# ATxmega128D4 device description
Architecture: AVR8_XMEGA; Family: AVR XMEGA
Registers are 8-bit, access not given, no defined reset value unless marked. A register's access mark holds for its fields unless they carry their own. Offsets are from the block's base; [hi:lo] are bit positions; lines under a group give offsets from that group; {n}, {i} and the like mark numbered series; 'fields as' and 'values as' point back to an identical list.

## RTC — Real-Time Counter
Instances: RTC 0x0400
0x00 CTRL — Control Register
  [2:0] PRESCALER — Prescaling Factor
    0=OFF (RTC Off); 1=DIV1 (RTC Clock); 2=DIV2 (RTC Clock / 2); 3=DIV8 (RTC Clock / 8); 4=DIV16 (RTC Clock / 16); 5=DIV64 (RTC Clock / 64); 6=DIV256 (RTC Clock / 256); 7=DIV1024 (RTC Clock / 1024)
0x01 STATUS
  [0] SYNCBUSY — Synchronization Busy Flag
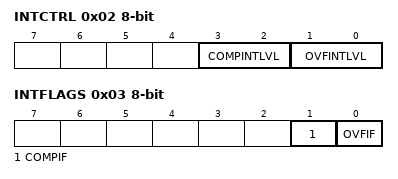
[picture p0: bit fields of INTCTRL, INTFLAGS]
0x02 INTCTRL — Interrupt Control Register
  [3:2] COMPINTLVL — Compare Match Interrupt Level
    0=OFF (Interrupt Disabled); 1=LO (Low Level); 2=MED (Medium Level); 3=HI (High Level)
  [1:0] OVFINTLVL — Overflow Interrupt Level
    values as COMPINTLVL
0x03 INTFLAGS — Interrupt Flags
  [1] COMPIF — Compare Match Interrupt Flag
  [0] OVFIF — Overflow Interrupt Flag
0x04 TEMP — Temporary register
0x08 CNT 16-bit — Count Register
0x0A PER 16-bit — Period Register
0x0C COMP 16-bit — Compare Register

## TWI — Two-Wire Interface
Instances: TWIC 0x480, TWIE 0x4A0
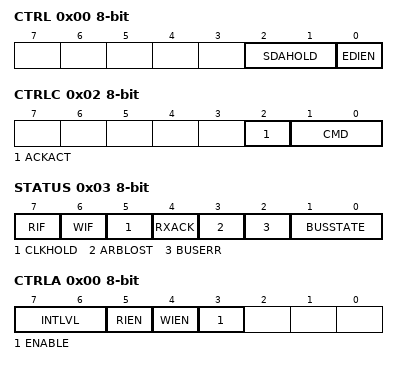
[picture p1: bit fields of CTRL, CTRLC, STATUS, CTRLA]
0x00 CTRL — TWI Common Control Register
  [2:1] SDAHOLD — SDA Hold Time Enable
    0=OFF (SDA Hold Time off); 1=50NS (SDA Hold Time 50 ns); 2=300NS (SDA Hold Time 300 ns); 3=400NS (SDA Hold Time 400 ns)
  [0] EDIEN — External Driver Interface Enable
0x01 MASTER group — TWI master module
  0x00 CTRLA — Control Register A
    [7:6] INTLVL — Interrupt Level
      0=OFF (Interrupt Disabled); 1=LO (Low Level); 2=MED (Medium Level); 3=HI (High Level)
    [5] RIEN — Read Interrupt Enable
    [4] WIEN — Write Interrupt Enable
    [3] ENABLE — Enable TWI Master
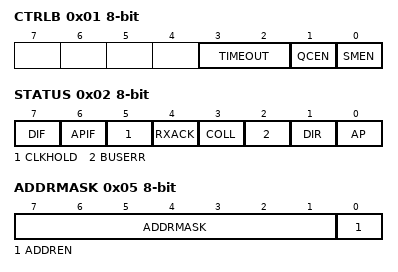
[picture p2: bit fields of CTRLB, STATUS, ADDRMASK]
  0x01 CTRLB — Control Register B
    [3:2] TIMEOUT — Inactive Bus Timeout
      0=DISABLED (Bus Timeout Disabled); 1=50US (50 Microseconds); 2=100US (100 Microseconds); 3=200US (200 Microseconds)
    [1] QCEN — Quick Command Enable
    [0] SMEN — Smart Mode Enable
  0x02 CTRLC — Control Register C
    [2] ACKACT — Acknowledge Action
    [1:0] CMD — Command
      0=NOACT (No Action); 1=REPSTART (Issue Repeated Start Condition); 2=RECVTRANS (Receive or Transmit Data); 3=STOP (Issue Stop Condition)
  0x03 STATUS
    [7] RIF — Read Interrupt Flag
    [6] WIF — Write Interrupt Flag
    [5] CLKHOLD — Clock Hold
    [4] RXACK — Received Acknowledge
    [3] ARBLOST — Arbitration Lost
    [2] BUSERR — Bus Error
    [1:0] BUSSTATE
      0=UNKNOWN (Unknown Bus State); 1=IDLE (Bus is Idle); 2=OWNER (This Module Controls The Bus); 3=BUSY (The Bus is Busy)
  0x04 BAUD — Baurd Rate Control Register
  0x05 ADDR — Address Register
  0x06 DATA
0x08 SLAVE group — TWI slave module
  0x00 CTRLA — Control Register A
    [7:6] INTLVL — Interrupt Level
      values as MASTER.CTRLA.INTLVL
    [5] DIEN — Data Interrupt Enable
    [4] APIEN — Address/Stop Interrupt Enable
    [3] ENABLE — Enable TWI Slave
    [2] PIEN — Stop Interrupt Enable
    [1] PMEN — Promiscuous Mode Enable
    [0] SMEN — Smart Mode Enable
  0x01 CTRLB — Control Register B
    [2] ACKACT — Acknowledge Action
    [1:0] CMD — Command
      0=NOACT (No Action); 2=COMPTRANS (Used To Complete a Transaction); 3=RESPONSE (Used in Response to Address/Data Interrupt)
  0x02 STATUS
    [7] DIF — Data Interrupt Flag
    [6] APIF — Address/Stop Interrupt Flag
    [5] CLKHOLD — Clock Hold
    [4] RXACK — Received Acknowledge
    [3] COLL — Collision
    [2] BUSERR — Bus Error
    [1] DIR — Read/Write Direction
    [0] AP — Slave Address or Stop
  0x03 ADDR — Address Register
  0x04 DATA
  0x05 ADDRMASK — Address Mask Register
    [7:1] ADDRMASK — Address Mask
    [0] ADDREN — Address Enable

## PORT — I/O Ports
Instances: PORTA 0x0600, PORTB 0x0620, PORTC 0x0640, PORTD 0x0660, PORTE 0x0680, PORTR 0x07E0
0x00 DIR — I/O Port Data Direction
0x01 DIRSET — I/O Port Data Direction Set
0x02 DIRCLR — I/O Port Data Direction Clear
0x03 DIRTGL — I/O Port Data Direction Toggle
0x04 OUT — I/O Port Output
0x05 OUTSET — I/O Port Output Set
0x06 OUTCLR — I/O Port Output Clear
0x07 OUTTGL — I/O Port Output Toggle
0x08 IN — I/O port Input
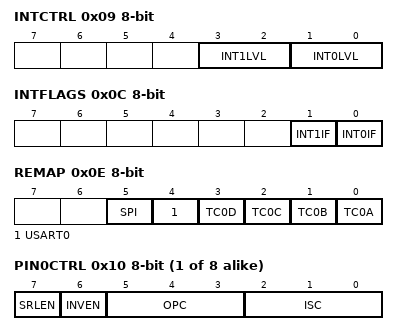
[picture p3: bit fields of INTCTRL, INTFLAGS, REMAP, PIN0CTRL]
0x09 INTCTRL — Interrupt Control Register
  [3:2] INT1LVL — Port Interrupt 1 Level
    0=OFF (Interrupt Disabled); 1=LO (Low Level); 2=MED (Medium Level); 3=HI (High Level)
  [1:0] INT0LVL — Port Interrupt 0 Level
    values as INT1LVL
0x0A INT0MASK — Port Interrupt 0 Mask
0x0B INT1MASK — Port Interrupt 1 Mask
0x0C INTFLAGS — Interrupt Flag Register
  [1] INT1IF — Port Interrupt 1 Flag
  [0] INT0IF — Port Interrupt 0 Flag
0x0E REMAP — Pin Remap Register (available for PORTC to PORTF only)
  [5] SPI — SPI Remap
  [4] USART0 — USART0 Remap
  [3] TC0D — Timer/Counter 0 Output Compare D
  [2] TC0C — Timer/Counter 0 Output Compare C
  [1] TC0B — Timer/Counter 0 Output Compare B
  [0] TC0A — Timer/Counter 0 Output Compare A
{0x10+i} PIN{i}CTRL (i=0..7) — Pin {i} Control Register
  [7] SRLEN — Slew Rate Enable
  [6] INVEN — Inverted I/O Enable
  [5:3] OPC — Output/Pull Configuration
    0=TOTEM (Totempole); 1=BUSKEEPER (Totempole w/ Bus keeper on Input and Output); 2=PULLDOWN (Totempole w/ Pull-down on Input); 3=PULLUP (Totempole w/ Pull-up on Input); 4=WIREDOR; 5=WIREDAND; 6=WIREDORPULL (Wired OR w/ Pull-down); 7=WIREDANDPULL (Wired AND w/ Pull-up)
  [2:0] ISC — Input/Sense Configuration
    0=BOTHEDGES (Sense Both Edges); 1=RISING (Sense Rising Edge); 2=FALLING (Sense Falling Edge); 3=LEVEL (Sense Level (Transparent For Events)); 7=INPUT_DISABLE (Disable Digital Input Buffer)
